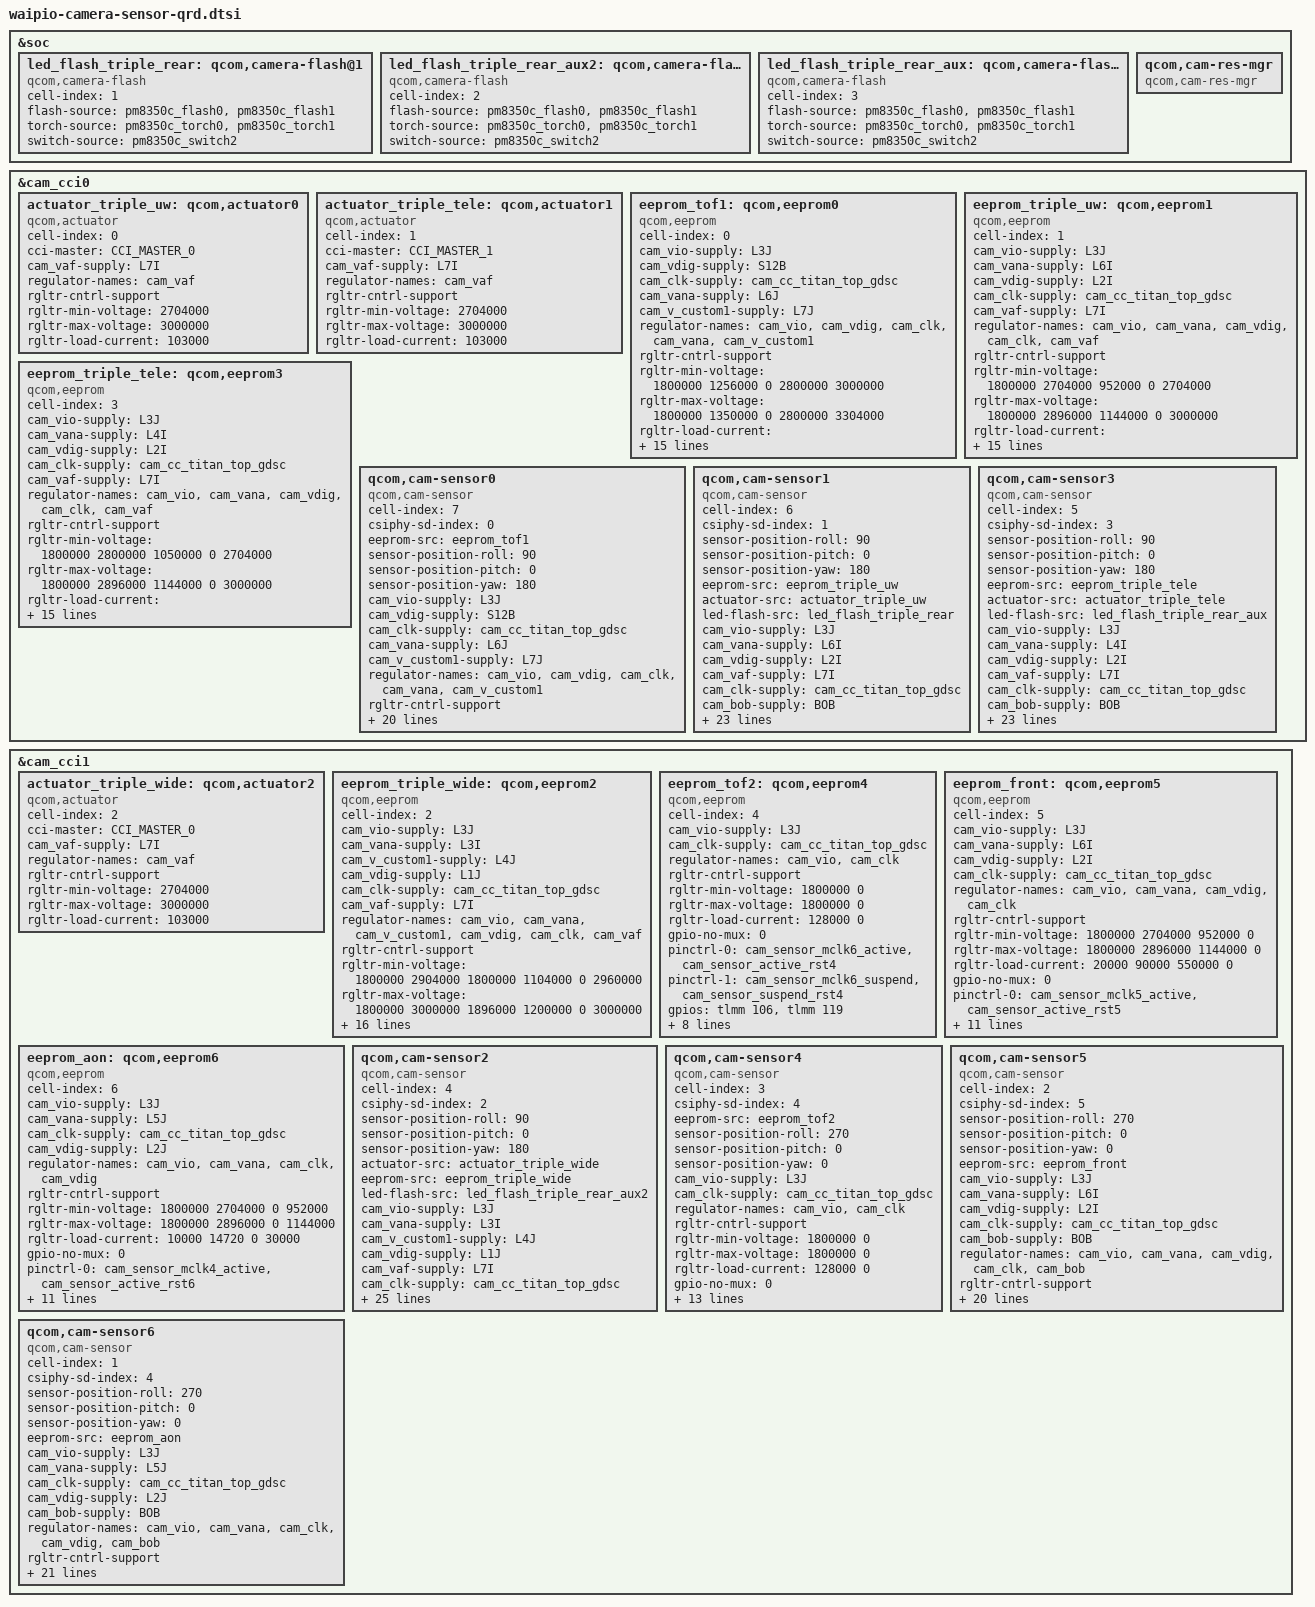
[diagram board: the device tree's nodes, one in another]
#include <dt-bindings/clock/qcom,camcc-waipio.h>
#include <dt-bindings/msm-camera.h>

&soc {
	led_flash_triple_rear: qcom,camera-flash@1 {
		cell-index = <1>;
		compatible = "qcom,camera-flash";
		flash-source = <&pm8350c_flash0 &pm8350c_flash1>;
		torch-source = <&pm8350c_torch0 &pm8350c_torch1>;
		switch-source = <&pm8350c_switch2>;
		status = "ok";
	};

	led_flash_triple_rear_aux2: qcom,camera-flash@2 {
		cell-index = <2>;
		compatible = "qcom,camera-flash";
		flash-source = <&pm8350c_flash0 &pm8350c_flash1>;
		torch-source = <&pm8350c_torch0 &pm8350c_torch1>;
		switch-source = <&pm8350c_switch2>;
		status = "ok";
	};

	led_flash_triple_rear_aux: qcom,camera-flash@3 {
		cell-index = <3>;
		compatible = "qcom,camera-flash";
		flash-source = <&pm8350c_flash0 &pm8350c_flash1>;
		torch-source = <&pm8350c_torch0 &pm8350c_torch1>;
		switch-source = <&pm8350c_switch2>;
		status = "ok";
	};

	qcom,cam-res-mgr {
		compatible = "qcom,cam-res-mgr";
		status = "ok";
	};
};

&cam_cci0 {
	actuator_triple_uw: qcom,actuator0 {
		cell-index = <0>;
		compatible = "qcom,actuator";
		cci-master = <CCI_MASTER_0>;
		cam_vaf-supply = <&L7I>;
		regulator-names = "cam_vaf";
		rgltr-cntrl-support;
		rgltr-min-voltage = <2704000>;
		rgltr-max-voltage = <3000000>;
		rgltr-load-current = <103000>;
		status = "ok";
	};

	actuator_triple_tele: qcom,actuator1 {
		cell-index = <1>;
		compatible = "qcom,actuator";
		cci-master = <CCI_MASTER_1>;
		cam_vaf-supply = <&L7I>;
		regulator-names = "cam_vaf";
		rgltr-cntrl-support;
		rgltr-min-voltage = <2704000>;
		rgltr-max-voltage = <3000000>;
		rgltr-load-current = <103000>;
		status = "ok";
	};

	eeprom_tof1: qcom,eeprom0 {
		cell-index = <0>;
		compatible = "qcom,eeprom";
		cam_vio-supply = <&L3J>;
		cam_vdig-supply = <&S12B>;
		cam_clk-supply = <&cam_cc_titan_top_gdsc>;
		cam_vana-supply = <&L6J>;
		cam_v_custom1-supply = <&L7J>;
		regulator-names = "cam_vio", "cam_vdig",
			"cam_clk", "cam_vana", "cam_v_custom1";
		rgltr-cntrl-support;
		rgltr-min-voltage = <1800000 1256000 0 2800000 3000000>;
		rgltr-max-voltage = <1800000 1350000 0 2800000 3304000>;
		rgltr-load-current = <155000 680000 0 50000 30000>;
		gpio-no-mux = <0>;
		pinctrl-names = "cam_default", "cam_suspend";
		pinctrl-0 = <&cam_sensor_mclk0_active
			&cam_sensor_active_rst0>;
		pinctrl-1 = <&cam_sensor_mclk0_suspend
			&cam_sensor_suspend_rst0>;
		gpios = <&tlmm 100 0>,
			<&tlmm 25 0>;
		gpio-reset = <1>;
		gpio-req-tbl-num = <0 1>;
		gpio-req-tbl-flags = <1 0>;
		gpio-req-tbl-label = "CAMIF_MCLK0",
					"CAM_RESET0";
		cci-master = <CCI_MASTER_0>;
		clocks = <&clock_camcc CAM_CC_MCLK0_CLK>;
		clock-names = "cam_clk";
		clock-cntl-level = "nominal";
		clock-rates = <24000000>;
		status = "ok";
	};

	eeprom_triple_uw: qcom,eeprom1 {
		cell-index = <1>;
		compatible = "qcom,eeprom";
		cam_vio-supply = <&L3J>;
		cam_vana-supply = <&L6I>;
		cam_vdig-supply = <&L2I>;
		cam_clk-supply = <&cam_cc_titan_top_gdsc>;
		cam_vaf-supply = <&L7I>;
		regulator-names = "cam_vio", "cam_vana", "cam_vdig",
			"cam_clk", "cam_vaf";
		rgltr-cntrl-support;
		rgltr-min-voltage = <1800000 2704000 952000 0 2704000>;
		rgltr-max-voltage = <1800000 2896000 1144000 0 3000000>;
		rgltr-load-current = <20000 90000 550000 0 103000>;
		gpio-no-mux = <0>;
		pinctrl-names = "cam_default", "cam_suspend";
		pinctrl-0 = <&cam_sensor_mclk1_active
				 &cam_sensor_active_rst1>;
		pinctrl-1 = <&cam_sensor_mclk1_suspend
				 &cam_sensor_suspend_rst1>;
		gpios = <&tlmm 101 0>,
			<&tlmm 24 0>;
		gpio-reset = <1>;
		gpio-req-tbl-num = <0 1>;
		gpio-req-tbl-flags = <1 0>;
		gpio-req-tbl-label = "CAMIF_MCLK1",
					"CAM_RESET1";
		cci-master = <CCI_MASTER_0>;
		clocks = <&clock_camcc CAM_CC_MCLK1_CLK>;
		clock-names = "cam_clk";
		clock-cntl-level = "nominal";
		clock-rates = <24000000>;
		status = "ok";
	};

	eeprom_triple_tele: qcom,eeprom3 {
		cell-index = <3>;
		compatible = "qcom,eeprom";
		cam_vio-supply = <&L3J>;
		cam_vana-supply = <&L4I>;
		cam_vdig-supply = <&L2I>;
		cam_clk-supply = <&cam_cc_titan_top_gdsc>;
		cam_vaf-supply = <&L7I>;
		regulator-names = "cam_vio", "cam_vana", "cam_vdig",
			"cam_clk", "cam_vaf";
		rgltr-cntrl-support;
		rgltr-min-voltage = <1800000 2800000 1050000 0 2704000>;
		rgltr-max-voltage = <1800000 2896000 1144000 0 3000000>;
		rgltr-load-current = <10000 52000 140400 0 103000>;
		gpio-no-mux = <0>;
		pinctrl-names = "cam_default", "cam_suspend";
		pinctrl-0 = <&cam_sensor_mclk3_active
				 &cam_sensor_active_rst3>;
		pinctrl-1 = <&cam_sensor_mclk3_suspend
				 &cam_sensor_suspend_rst3>;
		gpios = <&tlmm 103 0>,
			<&tlmm 120 0>;
		gpio-reset = <1>;
		gpio-req-tbl-num = <0 1>;
		gpio-req-tbl-flags = <1 0>;
		gpio-req-tbl-label = "CAMIF_MCLK3",
					"CAM_RESET3";
		cci-master = <CCI_MASTER_1>;
		clocks = <&clock_camcc CAM_CC_MCLK3_CLK>;
		clock-names = "cam_clk";
		clock-cntl-level = "nominal";
		clock-rates = <24000000>;
		status = "ok";
	};

	qcom,cam-sensor0 {
		cell-index = <7>;
		compatible = "qcom,cam-sensor";
		csiphy-sd-index = <0>;
		eeprom-src = <&eeprom_tof1>;
		sensor-position-roll = <90>;
		sensor-position-pitch = <0>;
		sensor-position-yaw = <180>;
		cam_vio-supply = <&L3J>;
		cam_vdig-supply = <&S12B>;
		cam_clk-supply = <&cam_cc_titan_top_gdsc>;
		cam_vana-supply = <&L6J>;
		cam_v_custom1-supply = <&L7J>;
		regulator-names = "cam_vio", "cam_vdig",
			"cam_clk", "cam_vana", "cam_v_custom1";
		rgltr-cntrl-support;
		rgltr-min-voltage = <1800000 1256000 0 2800000 3000000>;
		rgltr-max-voltage = <1800000 1350000 0 2800000 3304000>;
		rgltr-load-current = <155000 680000 0 50000 30000>;
		gpio-no-mux = <0>;
		pinctrl-names = "cam_default", "cam_suspend";
		pinctrl-0 = <&cam_sensor_mclk0_active
			&cam_sensor_active_rst0>;
		pinctrl-1 = <&cam_sensor_mclk0_suspend
			&cam_sensor_suspend_rst0>;
		gpios = <&tlmm 100 0>,
			<&tlmm 25 0>;
		gpio-reset = <1>;
		gpio-req-tbl-num = <0 1>;
		gpio-req-tbl-flags = <1 0>;
		gpio-req-tbl-label = "CAMIF_MCLK0",
					"CAM_RESET0";
		cci-master = <CCI_MASTER_0>;
		clocks = <&clock_camcc CAM_CC_MCLK0_CLK>;
		clock-names = "cam_clk";
		clock-cntl-level = "nominal";
		clock-rates = <24000000>;
		status = "ok";
	};

	qcom,cam-sensor1 {
		cell-index = <6>;
		compatible = "qcom,cam-sensor";
		csiphy-sd-index = <1>;
		sensor-position-roll = <90>;
		sensor-position-pitch = <0>;
		sensor-position-yaw = <180>;
		eeprom-src = <&eeprom_triple_uw>;
		actuator-src = <&actuator_triple_uw>;
		led-flash-src = <&led_flash_triple_rear>;
		cam_vio-supply = <&L3J>;
		cam_vana-supply = <&L6I>;
		cam_vdig-supply = <&L2I>;
		cam_vaf-supply = <&L7I>;
		cam_clk-supply = <&cam_cc_titan_top_gdsc>;
		cam_bob-supply = <&BOB>;
		regulator-names = "cam_vio", "cam_vana", "cam_vdig",
			"cam_vaf", "cam_clk", "cam_bob";
		rgltr-cntrl-support;
		rgltr-min-voltage = <1800000 2704000 952000 2704000 0 3008000>;
		rgltr-max-voltage = <1800000 2896000 1144000 3000000 0 3960000>;
		rgltr-load-current = <20000 90000 550000 103000 0 7070000>;
		gpio-no-mux = <0>;
		pinctrl-names = "cam_default", "cam_suspend";
		pinctrl-0 = <&cam_sensor_mclk1_active
				 &cam_sensor_active_rst1>;
		pinctrl-1 = <&cam_sensor_mclk1_suspend
				 &cam_sensor_suspend_rst1>;
		gpios = <&tlmm 101 0>,
			<&tlmm 24 0>;
		gpio-reset = <1>;
		gpio-req-tbl-num = <0 1>;
		gpio-req-tbl-flags = <1 0>;
		gpio-req-tbl-label = "CAMIF_MCLK1",
					"CAM_RESET1";
		cci-master = <CCI_MASTER_0>;
		clocks = <&clock_camcc CAM_CC_MCLK1_CLK>;
		clock-names = "cam_clk";
		clock-cntl-level = "nominal";
		clock-rates = <24000000>;
		status = "ok";
	};

	qcom,cam-sensor3 {
		cell-index = <5>;
		compatible = "qcom,cam-sensor";
		csiphy-sd-index = <3>;
		sensor-position-roll = <90>;
		sensor-position-pitch = <0>;
		sensor-position-yaw = <180>;
		eeprom-src = <&eeprom_triple_tele>;
		actuator-src = <&actuator_triple_tele>;
		led-flash-src = <&led_flash_triple_rear_aux>;
		cam_vio-supply = <&L3J>;
		cam_vana-supply = <&L4I>;
		cam_vdig-supply = <&L2I>;
		cam_vaf-supply = <&L7I>;
		cam_clk-supply = <&cam_cc_titan_top_gdsc>;
		cam_bob-supply = <&BOB>;
		regulator-names = "cam_vio", "cam_vana", "cam_vdig",
			"cam_vaf", "cam_clk", "cam_bob";
		rgltr-cntrl-support;
		rgltr-min-voltage = <1800000 2800000 1050000 2704000 0 3008000>;
		rgltr-max-voltage = <1800000 2896000 1144000 3000000 0 3960000>;
		rgltr-load-current = <10000 52000 140400 103000 0 7070000>;
		gpio-no-mux = <0>;
		pinctrl-names = "cam_default", "cam_suspend";
		pinctrl-0 = <&cam_sensor_mclk3_active
				 &cam_sensor_active_rst3>;
		pinctrl-1 = <&cam_sensor_mclk3_suspend
				 &cam_sensor_suspend_rst3>;
		gpios = <&tlmm 103 0>,
			<&tlmm 120 0>;
		gpio-reset = <1>;
		gpio-req-tbl-num = <0 1>;
		gpio-req-tbl-flags = <1 0>;
		gpio-req-tbl-label = "CAMIF_MCLK3",
					"CAM_RESET3";
		cci-master = <CCI_MASTER_1>;
		clocks = <&clock_camcc CAM_CC_MCLK3_CLK>;
		clock-names = "cam_clk";
		clock-cntl-level = "nominal";
		clock-rates = <24000000>;
		status = "ok";
	};
};

&cam_cci1 {
	actuator_triple_wide: qcom,actuator2 {
		cell-index = <2>;
		compatible = "qcom,actuator";
		cci-master = <CCI_MASTER_0>;
		cam_vaf-supply = <&L7I>;
		regulator-names = "cam_vaf";
		rgltr-cntrl-support;
		rgltr-min-voltage = <2704000>;
		rgltr-max-voltage = <3000000>;
		rgltr-load-current = <103000>;
		status = "ok";
	};

	eeprom_triple_wide: qcom,eeprom2 {
		cell-index = <2>;
		compatible = "qcom,eeprom";
		cam_vio-supply = <&L3J>;
		cam_vana-supply = <&L3I>;
		cam_v_custom1-supply = <&L4J>;
		cam_vdig-supply = <&L1J>;
		cam_clk-supply = <&cam_cc_titan_top_gdsc>;
		cam_vaf-supply = <&L7I>;
		regulator-names = "cam_vio", "cam_vana", "cam_v_custom1",
			"cam_vdig", "cam_clk", "cam_vaf";
		rgltr-cntrl-support;
		rgltr-min-voltage = <1800000 2904000 1800000 1104000 0 2960000>;
		rgltr-max-voltage = <1800000 3000000 1896000 1200000 0 3000000>;
		rgltr-load-current = <10000 139300 90100 872000 0 103000>;
		gpio-no-mux = <0>;
		pinctrl-names = "cam_default", "cam_suspend";
		pinctrl-0 = <&cam_sensor_mclk2_active
				&cam_sensor_active_rst2>;
		pinctrl-1 = <&cam_sensor_mclk2_suspend
				&cam_sensor_suspend_rst2>;
		gpios = <&tlmm 102 0>,
			<&tlmm 117 0>;
		gpio-reset = <1>;
		gpio-req-tbl-num = <0 1>;
		gpio-req-tbl-flags = <1 0>;
		gpio-req-tbl-label = "CAMIF_MCLK2",
					"CAM_RESET2";
		cci-master = <CCI_MASTER_0>;
		clocks = <&clock_camcc CAM_CC_MCLK2_CLK>;
		clock-names = "cam_clk";
		clock-cntl-level = "nominal";
		clock-rates = <24000000>;
		status = "ok";
	};

	eeprom_tof2: qcom,eeprom4 {
		cell-index = <4>;
		compatible = "qcom,eeprom";
		cam_vio-supply = <&L3J>;
		cam_clk-supply = <&cam_cc_titan_top_gdsc>;
		regulator-names = "cam_vio", "cam_clk";
		rgltr-cntrl-support;
		rgltr-min-voltage = <1800000 0>;
		rgltr-max-voltage = <1800000 0>;
		rgltr-load-current = <128000 0>;
		gpio-no-mux = <0>;
		pinctrl-names = "cam_default", "cam_suspend";
		pinctrl-0 = <&cam_sensor_mclk6_active
			&cam_sensor_active_rst4>;
		pinctrl-1 = <&cam_sensor_mclk6_suspend
			&cam_sensor_suspend_rst4>;
		gpios = <&tlmm 106 0>,
			<&tlmm 119 0>;
		gpio-reset = <1>;
		gpio-req-tbl-num = <0 1>;
		gpio-req-tbl-flags = <1 0>;
		gpio-req-tbl-label = "CAMIF_MCLK6",
			"CAM_RESET4";
		cci-master = <CCI_MASTER_0>;
		clocks = <&clock_camcc CAM_CC_MCLK6_CLK>;
		clock-names = "cam_clk";
		clock-cntl-level = "nominal";
		clock-rates = <24000000>;
		status = "ok";
	};

	eeprom_front: qcom,eeprom5 {
		cell-index = <5>;
		compatible = "qcom,eeprom";
		cam_vio-supply = <&L3J>;
		cam_vana-supply = <&L6I>;
		cam_vdig-supply = <&L2I>;
		cam_clk-supply = <&cam_cc_titan_top_gdsc>;
		regulator-names = "cam_vio", "cam_vana", "cam_vdig",
			"cam_clk";
		rgltr-cntrl-support;
		rgltr-min-voltage = <1800000 2704000 952000 0>;
		rgltr-max-voltage = <1800000 2896000 1144000 0>;
		rgltr-load-current = <20000 90000 550000 0>;
		gpio-no-mux = <0>;
		pinctrl-names = "cam_default", "cam_suspend";
		pinctrl-0 = <&cam_sensor_mclk5_active
				 &cam_sensor_active_rst5>;
		pinctrl-1 = <&cam_sensor_mclk5_suspend
				 &cam_sensor_suspend_rst5>;
		gpios = <&tlmm 105 0>,
			<&tlmm 118 0>;
		gpio-reset = <1>;
		gpio-req-tbl-num = <0 1>;
		gpio-req-tbl-flags = <1 0>;
		gpio-req-tbl-label = "CAMIF_MCLK5",
					"CAM_RESET5";
		cci-master = <CCI_MASTER_0>;
		clocks = <&clock_camcc CAM_CC_MCLK5_CLK>;
		clock-names = "cam_clk";
		clock-cntl-level = "nominal";
		clock-rates = <24000000>;
		status = "ok";
	};

	eeprom_aon: qcom,eeprom6 {
		cell-index = <6>;
		compatible = "qcom,eeprom";
		cam_vio-supply = <&L3J>;
		cam_vana-supply = <&L5J>;
		cam_clk-supply = <&cam_cc_titan_top_gdsc>;
		cam_vdig-supply = <&L2J>;
		regulator-names = "cam_vio", "cam_vana","cam_clk", "cam_vdig";
		rgltr-cntrl-support;
		rgltr-min-voltage = <1800000 2704000 0 952000>;
		rgltr-max-voltage = <1800000 2896000 0 1144000>;
		rgltr-load-current = <10000 14720 0 30000>;
		gpio-no-mux = <0>;
		pinctrl-names = "cam_default", "cam_suspend";
		pinctrl-0 = <&cam_sensor_mclk4_active
				 &cam_sensor_active_rst6>;
		pinctrl-1 = <&cam_sensor_mclk4_suspend
				 &cam_sensor_suspend_rst6>;
		gpios = <&tlmm 104 0>,
			<&tlmm 108 0>;
		gpio-reset = <1>;
		gpio-req-tbl-num = <0 1>;
		gpio-req-tbl-flags = <1 0>;
		gpio-req-tbl-label = "CAMIF_MCLK4",
					"CAM_RESET6";
		cci-master = <CCI_MASTER_1>;
		clocks = <&clock_camcc CAM_CC_MCLK4_CLK>;
		clock-names = "cam_clk";
		clock-cntl-level = "nominal";
		clock-rates = <24000000>;
		status = "ok";
	};

	qcom,cam-sensor2 {
		cell-index = <4>;
		compatible = "qcom,cam-sensor";
		csiphy-sd-index = <2>;
		sensor-position-roll = <90>;
		sensor-position-pitch = <0>;
		sensor-position-yaw = <180>;
		actuator-src = <&actuator_triple_wide>;
		eeprom-src = <&eeprom_triple_wide>;
		led-flash-src = <&led_flash_triple_rear_aux2>;
		cam_vio-supply = <&L3J>;
		cam_vana-supply = <&L3I>;
		cam_v_custom1-supply = <&L4J>;
		cam_vdig-supply = <&L1J>;
		cam_vaf-supply = <&L7I>;
		cam_clk-supply = <&cam_cc_titan_top_gdsc>;
		cam_bob-supply = <&BOB>;
		regulator-names = "cam_vio", "cam_vana", "cam_v_custom1",
			"cam_vdig", "cam_vaf", "cam_clk", "cam_bob";
		rgltr-cntrl-support;
		rgltr-min-voltage = <1800000 2904000 1800000 1104000 2704000 0 3008000>;
		rgltr-max-voltage = <1800000 3000000 1896000 1200000 3000000 0 3960000>;
		rgltr-load-current = <10000 139300 90100 872000 103000 0 7070000>;
		gpio-no-mux = <0>;
		pinctrl-names = "cam_default", "cam_suspend";
		pinctrl-0 = <&cam_sensor_mclk2_active
				&cam_sensor_active_rst2>;
		pinctrl-1 = <&cam_sensor_mclk2_suspend
				&cam_sensor_suspend_rst2>;
		gpios = <&tlmm 102 0>,
			<&tlmm 117 0>;
		gpio-reset = <1>;
		gpio-req-tbl-num = <0 1>;
		gpio-req-tbl-flags = <1 0>;
		gpio-req-tbl-label = "CAMIF_MCLK2",
					"CAM_RESET2";
		cci-master = <CCI_MASTER_0>;
		clocks = <&clock_camcc CAM_CC_MCLK2_CLK>;
		clock-names = "cam_clk";
		clock-cntl-level = "nominal";
		clock-rates = <24000000>;
		status = "ok";
	};

	qcom,cam-sensor4 {
		cell-index = <3>;
		compatible = "qcom,cam-sensor";
		csiphy-sd-index = <4>;
		eeprom-src = <&eeprom_tof2>;
		sensor-position-roll = <270>;
		sensor-position-pitch = <0>;
		sensor-position-yaw = <0>;
		cam_vio-supply = <&L3J>;
		cam_clk-supply = <&cam_cc_titan_top_gdsc>;
		regulator-names = "cam_vio", "cam_clk";
		rgltr-cntrl-support;
		rgltr-min-voltage = <1800000 0>;
		rgltr-max-voltage = <1800000 0>;
		rgltr-load-current = <128000 0>;
		gpio-no-mux = <0>;
		pinctrl-names = "cam_default", "cam_suspend";
		pinctrl-0 = <&cam_sensor_mclk6_active
			&cam_sensor_active_rst4>;
		pinctrl-1 = <&cam_sensor_mclk6_suspend
			&cam_sensor_suspend_rst4>;
		gpios = <&tlmm 106 0>,
			<&tlmm 119 0>;
		gpio-reset = <1>;
		gpio-req-tbl-num = <0 1>;
		gpio-req-tbl-flags = <1 0>;
		gpio-req-tbl-label = "CAMIF_MCLK6",
			"CAM_RESET4";
		cci-master = <CCI_MASTER_0>;
		clocks = <&clock_camcc CAM_CC_MCLK6_CLK>;
		clock-names = "cam_clk";
		clock-cntl-level = "nominal";
		clock-rates = <24000000>;
		status = "ok";
	};

	qcom,cam-sensor5 {
		cell-index = <2>;
		compatible = "qcom,cam-sensor";
		csiphy-sd-index = <5>;
		sensor-position-roll = <270>;
		sensor-position-pitch = <0>;
		sensor-position-yaw = <0>;
		eeprom-src = <&eeprom_front>;
		cam_vio-supply = <&L3J>;
		cam_vana-supply = <&L6I>;
		cam_vdig-supply = <&L2I>;
		cam_clk-supply = <&cam_cc_titan_top_gdsc>;
		cam_bob-supply = <&BOB>;
		regulator-names = "cam_vio", "cam_vana", "cam_vdig",
			"cam_clk", "cam_bob";
		rgltr-cntrl-support;
		rgltr-min-voltage = <1800000 2704000 952000 0 3008000>;
		rgltr-max-voltage = <1800000 2896000 1144000 0 3960000>;
		rgltr-load-current = <20000 90000 550000 0 7070000>;
		gpio-no-mux = <0>;
		pinctrl-names = "cam_default", "cam_suspend";
		pinctrl-0 = <&cam_sensor_mclk5_active
				 &cam_sensor_active_rst5>;
		pinctrl-1 = <&cam_sensor_mclk5_suspend
				 &cam_sensor_suspend_rst5>;
		gpios = <&tlmm 105 0>,
			<&tlmm 118 0>;
		gpio-reset = <1>;
		gpio-req-tbl-num = <0 1>;
		gpio-req-tbl-flags = <1 0>;
		gpio-req-tbl-label = "CAMIF_MCLK5",
					"CAM_RESET5";
		cci-master = <CCI_MASTER_0>;
		clocks = <&clock_camcc CAM_CC_MCLK5_CLK>;
		clock-names = "cam_clk";
		clock-cntl-level = "nominal";
		clock-rates = <24000000>;
		status = "ok";
	};

	qcom,cam-sensor6 {
		cell-index = <1>;
		compatible = "qcom,cam-sensor";
		csiphy-sd-index = <4>;
		sensor-position-roll = <270>;
		sensor-position-pitch = <0>;
		sensor-position-yaw = <0>;
		eeprom-src = <&eeprom_aon>;
		cam_vio-supply = <&L3J>;
		cam_vana-supply = <&L5J>;
		cam_clk-supply = <&cam_cc_titan_top_gdsc>;
		cam_vdig-supply = <&L2J>;
		cam_bob-supply = <&BOB>;
		regulator-names = "cam_vio", "cam_vana", "cam_clk", "cam_vdig",
			"cam_bob";
		rgltr-cntrl-support;
		aon-user;
		rgltr-min-voltage = <1800000 2704000 0 952000 3008000>;
		rgltr-max-voltage = <1800000 2896000 0 1144000 3960000>;
		rgltr-load-current = <10000 14720 0 30000 7070000>;
		gpio-no-mux = <0>;
		pinctrl-names = "cam_default", "cam_suspend";
		pinctrl-0 = <&cam_sensor_mclk4_active
				 &cam_sensor_active_rst6>;
		pinctrl-1 = <&cam_sensor_mclk4_suspend
				 &cam_sensor_suspend_rst6>;
		gpios = <&tlmm 104 0>,
			<&tlmm 108 0>;
		gpio-reset = <1>;
		gpio-req-tbl-num = <0 1>;
		gpio-req-tbl-flags = <1 0>;
		gpio-req-tbl-label = "CAMIF_MCLK4",
					"CAM_RESET6";
		cci-master = <CCI_MASTER_1>;
		clocks = <&clock_camcc CAM_CC_MCLK4_CLK>;
		clock-names = "cam_clk";
		clock-cntl-level = "nominal";
		clock-rates = <24000000>;
		status = "ok";
	};
};
